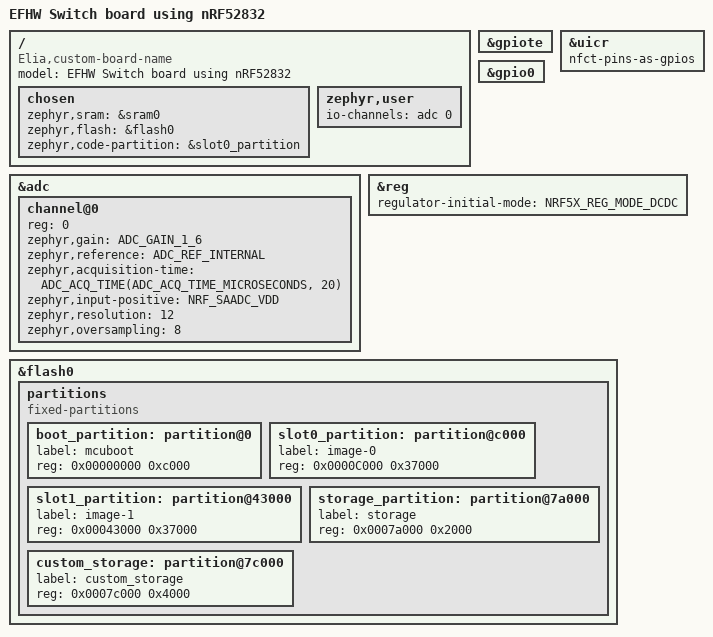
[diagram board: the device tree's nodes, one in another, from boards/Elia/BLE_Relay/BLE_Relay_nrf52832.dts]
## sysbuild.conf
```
SB_CONFIG_BOOTLOADER_MCUBOOT=y
SB_CONFIG_BOOT_SIGNATURE_KEY_FILE="${APP_DIR}/mykey.pem"
```

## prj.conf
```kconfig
#
# Copyright (c) 2020 Nordic Semiconductor
#
# SPDX-License-Identifier: LicenseRef-Nordic-5-Clause
#
CONFIG_NCS_SAMPLES_DEFAULTS=y
CONFIG_DK_LIBRARY=n
CONFIG_SYSTEM_WORKQUEUE_STACK_SIZE=2048
CONFIG_CLOCK_CONTROL_NRF_K32SRC_RC=y
CONFIG_SYSTEM_CLOCK_WAIT_FOR_STABILITY=y
CONFIG_CLOCK_CONTROL_NRF_K32SRC_500PPM=y  # Adjust as needed for power consumption vs. accuracy

CONFIG_BT_CTLR_TX_PWR_PLUS_4=y
CONFIG_FPU=y
CONFIG_CBPRINTF_FP_SUPPORT=y
CONFIG_CBPRINTF_FP_A_SUPPORT=y
CONFIG_BT_GAP_AUTO_UPDATE_CONN_PARAMS=y
CONFIG_BT_GAP_PERIPHERAL_PREF_PARAMS=y
CONFIG_ASSERT=n

CONFIG_BT_PERIPHERAL_PREF_MIN_INT=200
CONFIG_BT_PERIPHERAL_PREF_MAX_INT=200
CONFIG_BT_PERIPHERAL_PREF_LATENCY=0
CONFIG_BT_PERIPHERAL_PREF_TIMEOUT=200

CONFIG_ARM_MPU=y
CONFIG_HW_STACK_PROTECTION=y

CONFIG_CONSOLE=y
CONFIG_UART_CONSOLE=n
CONFIG_RTT_CONSOLE=y
CONFIG_LOG=y
CONFIG_USE_SEGGER_RTT=y
CONFIG_ADC=y
CONFIG_BT=y
CONFIG_BT_PERIPHERAL=y
CONFIG_BT_DEVICE_NAME="BR1"
CONFIG_BT_MAX_CONN=1
CONFIG_BT_SMP=y

# Enable the BMS service
CONFIG_BT_BMS=y

# Enable bonding
CONFIG_BT_SETTINGS=y
CONFIG_FLASH=y
CONFIG_FLASH_PAGE_LAYOUT=y
CONFIG_FLASH_MAP=y
CONFIG_NVS=y
CONFIG_SETTINGS_NVS=y
CONFIG_SETTINGS=y
CONFIG_BT_DEVICE_NAME_DYNAMIC=y

CONFIG_BT_SETTINGS_CCC_LAZY_LOADING=n

CONFIG_BOOTLOADER_MCUBOOT=y
#CONFIG_MCUMGR=y
#CONFIG_IMG_MANAGER=y
#CONFIG_STREAM_FLASH=y
#CONFIG_ZCBOR=y
#CONFIG_NET_BUF=y

CONFIG_NCS_SAMPLE_MCUMGR_BT_OTA_DFU=y
# CONFIG_MCUMGR=y
# CONFIG_NET_BUF=y
# CONFIG_ZCBOR=y
# CONFIG_CRC=y
# CONFIG_MCUMGR_TRANSPORT_BT=y
# CONFIG_MCUMGR_TRANSPORT_BT_CONN_PARAM_CONTROL=y
# CONFIG_IMG_MANAGER=y
# CONFIG_STREAM_FLASH=y
# CONFIG_MCUMGR_GRP_IMG=y
# CONFIG_MCUMGR_GRP_OS=y
# CONFIG_MCUMGR_GRP_OS_BOOTLOADER_INFO=y
# CONFIG_MCUMGR_TRANSPORT_BT_REASSEMBLY=y
# CONFIG_NCS_SAMPLE_MCUMGR_BT_OTA_DFU_SPEEDUP=y  

CONFIG_SIZE_OPTIMIZATIONS=y

CONFIG_TIMESLICING=n
#CONFIG_MINIMAL_LIBC_MALLOC=n

# Interrupts
CONFIG_DYNAMIC_INTERRUPTS=n
CONFIG_IRQ_OFFLOAD=n

# Boot
CONFIG_BOOT_BANNER=n
CONFIG_BOOT_DELAY=0

# Interrupts
CONFIG_DYNAMIC_INTERRUPTS=n
CONFIG_IRQ_OFFLOAD=n

# Drivers and peripherals
CONFIG_I2C=n
CONFIG_WATCHDOG=y
CONFIG_GPIO=y
CONFIG_SPI=n
CONFIG_SERIAL=y
```

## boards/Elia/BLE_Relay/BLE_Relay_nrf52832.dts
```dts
/dts-v1/;
#include <nordic/nrf52832_qfaa.dtsi>
#include "BLE_Relay-pinctrl.dtsi"

/ {
	model = "EFHW Switch board using nRF52832";
	compatible = "Elia,custom-board-name";

	chosen {
		zephyr,sram = &sram0;
		zephyr,flash = &flash0;
		zephyr,code-partition = &slot0_partition;
	};

	zephyr,user {
		io-channels = <&adc 0>;
	};
};

&adc {
	#address-cells = <1>;
	#size-cells = <0>;
	status = "okay";
	channel@0 {
		reg = <0>;
		zephyr,gain = "ADC_GAIN_1_6";
		zephyr,reference = "ADC_REF_INTERNAL";
		zephyr,acquisition-time = <ADC_ACQ_TIME(ADC_ACQ_TIME_MICROSECONDS, 20)>;
		zephyr,input-positive = <NRF_SAADC_VDD>;
		zephyr,resolution = <12>;
		zephyr,oversampling = <8>;
	};
};

/* &uicr {
	gpio-as-nreset;
}; */

&gpiote {
	status = "okay";
};

&uicr { nfct-pins-as-gpios; };
	
&gpio0 {
	status = "okay";
};

&reg {
	regulator-initial-mode = <NRF5X_REG_MODE_DCDC>;
};

&flash0 {
	partitions {
		compatible = "fixed-partitions";
		#address-cells = <1>;
		#size-cells = <1>;

		boot_partition: partition@0 {
			label = "mcuboot";
			reg = <0x00000000 0xc000>;
		};
		slot0_partition: partition@c000 {
			label = "image-0";
			reg = <0x0000C000 0x37000>;
		};
		slot1_partition: partition@43000 {
			label = "image-1";
			reg = <0x00043000 0x37000>;
		};
		storage_partition: partition@7a000 {
			label = "storage";
			reg = <0x0007a000 0x2000>;
		};
		custom_storage: partition@7c000 {
			label = "custom_storage";
			reg = <0x0007c000 0x4000>;
		};
	};
};
```

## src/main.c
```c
// SPDX-License-Identifier: GPL-3.0-or-later
// Copyright (c) 2024-2026 Elia Chiarucci

#include <zephyr/types.h>
#include <stddef.h>
#include <string.h>
#include <errno.h>
#include <zephyr/sys/printk.h>
#include <zephyr/sys/byteorder.h>
#include <zephyr/kernel.h>
#include <zephyr/logging/log.h>
#include <soc.h>
#include <zephyr/settings/settings.h>
#include <nrfx_gpiote.h>

LOG_MODULE_REGISTER(ble_relay, LOG_LEVEL_DBG);

#include "storage_manager.h"
#include "gpio_manager.h"
#include "status_led.h"
#include "adc.h"
#include "ble_manager.h"
#include "watchdog.h"

struct k_timer update_led_status_timer;

int main(void)
{
	watchdog_start();
	storage_manager_init();
	init_hw_revision();
	gpio_start();
	adc_start();
	status_led_init();
	ble_start();

	// Feed from the lowest-priority thread: if the kernel hangs or a higher-priority thread
	// never yields, feeding stops and the watchdog resets the switch
	k_thread_priority_set(k_current_get(), K_LOWEST_APPLICATION_THREAD_PRIO);
	for (;;)
	{
		watchdog_feed();
		k_sleep(K_MSEC(WATCHDOG_FEED_INTERVAL_MS));
	}
}
```

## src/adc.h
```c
// SPDX-License-Identifier: GPL-3.0-or-later
// Copyright (c) 2024-2026 Elia Chiarucci

#pragma once

#include <zephyr/drivers/adc.h>
#include <zephyr/logging/log.h>

static const struct adc_dt_spec adc_channel = ADC_DT_SPEC_GET_BY_IDX(DT_PATH(zephyr_user), 0);

int16_t buf; // Buffer for ADC result
struct adc_sequence sequence = {
	.buffer = &buf,
	.buffer_size = sizeof(buf),
};

float get_battery_voltage()
{
	adc_read_dt(&adc_channel, &sequence);
	float voltage_value = (buf * 3.6) / 4096 + 0.05;
	return voltage_value;
}

int adc_start()
{
	int err;
	if (!adc_is_ready_dt(&adc_channel))
	{
		LOG_ERR("ADC controller devivce %s not ready", adc_channel.dev->name);
		return 0;
	}

	err = adc_channel_setup_dt(&adc_channel);
	if (err < 0)
	{
		LOG_ERR("Could not setup channel #%d (%d)", 2, err);
		return 0;
	}
	else
	{
		LOG_INF("Correctly set up ADC!");
	}

	err = adc_sequence_init_dt(&adc_channel, &sequence);
	if (err < 0)
	{
		LOG_ERR("Could not initalize sequnce");
		return 0;
	}
}

// Read handler for the battery level characteristic
static ssize_t read_battery_level(struct bt_conn *conn, const struct bt_gatt_attr *attr, void *buf,
								  uint16_t len, uint16_t offset)
{
	int16_t battery_voltage = get_battery_voltage() * 100;
	// Simply return the battery level (percent)
	return bt_gatt_attr_read(conn, attr, buf, len, offset, &battery_voltage,
							 sizeof(battery_voltage));
}
```

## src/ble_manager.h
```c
// SPDX-License-Identifier: GPL-3.0-or-later
// Copyright (c) 2024-2026 Elia Chiarucci

#pragma once

#include <bluetooth/services/bms.h>
#include <zephyr/bluetooth/bluetooth.h>
#include <zephyr/bluetooth/conn.h>
#include <zephyr/bluetooth/gatt.h>
#include <zephyr/bluetooth/hci.h>
#include <zephyr/bluetooth/uuid.h>
#include <zephyr/toolchain.h>

#define DEVICE_NAME CONFIG_BT_DEVICE_NAME
#define DEVICE_NAME_LEN (sizeof(DEVICE_NAME) - 1)

/* Authorization code for Bond Management Service
 * In hex: {0x41, 0x42, 0x43, 0x44}
 */
static const uint8_t bms_auth_code[] = {'A', 'B', 'C', 'D'};

#define CUSTOM_SERVICE_UUID                                                    \
  BT_UUID_128_ENCODE(0x67d03ad6, 0x34ba, 0x450a, 0xa39c, 0x00805f9b34fb)

#define BT_UUID_AUTOMATION_IO BT_UUID_DECLARE_16(0x1815)
#define BT_UUID_DIGITAL BT_UUID_DECLARE_16(0x2A56)

#define BT_UUID_BATTERY BT_UUID_DECLARE_16(0x180F)
#define BT_UUID_BATTERY_LEVEL BT_UUID_DECLARE_16(0x2A19)
#define BT_UUID_PRESENTATION_FORMAT BT_UUID_DECLARE_16(0x2904)

#define BT_UUID_CUSTOM_DEVICE_NAME_VAL                                         \
  BT_UUID_128_ENCODE(0x397bfacd, 0xf6c0, 0x470e, 0x8c72, 0x5b17d34e1259)
#define BT_UUID_CUSTOM_DEVICE_NAME                                             \
  BT_UUID_DECLARE_128(BT_UUID_CUSTOM_DEVICE_NAME_VAL)

#define BT_UUID_DEVICE_INFO                                                    \
  BT_UUID_DECLARE_16(0x180A) // Device Information Service
#define BT_UUID_FIRMWARE_REVISION                                              \
  BT_UUID_DECLARE_16(0x2A26) // Firmware Revision String
#define BT_UUID_HARDWARE_REVISION                                              \
  BT_UUID_DECLARE_16(0x2A27) // Hardware Revision String
#define BT_UUID_MODEL_NUMBER                                                   \
  BT_UUID_DECLARE_16(0x2A24) // Model Number String0x2A24

static const struct bt_le_conn_param *conn_params = BT_LE_CONN_PARAM(
    CONFIG_BT_PERIPHERAL_PREF_MIN_INT, CONFIG_BT_PERIPHERAL_PREF_MAX_INT,
    CONFIG_BT_PERIPHERAL_PREF_LATENCY, CONFIG_BT_PERIPHERAL_PREF_TIMEOUT);

// Presentation Format Descriptor for Voltage Level (scaled by 100, unit: volts)
static const uint8_t voltage_level_cpf[7] = {
    0x10, // Format: unsigned 16-bit integer
    0x00, // Exponent: no scaling (1.0)
    0x00, // Unit: Volts (0x2703)
    0x03, // Unit: Volts (0x2703)
    0x00, // Additional flags (reserved)
    0x00, // Reserved
    0x00  // Reserved
};

static const struct bt_data ad[] = {
    BT_DATA_BYTES(BT_DATA_FLAGS, (BT_LE_AD_GENERAL | BT_LE_AD_NO_BREDR)),
    BT_DATA(BT_DATA_NAME_COMPLETE, DEVICE_NAME, DEVICE_NAME_LEN),
};

static const struct bt_data sd[] = {
    BT_DATA_BYTES(BT_DATA_UUID128_ALL, CUSTOM_SERVICE_UUID),
};

static ssize_t read_firmware_revision(struct bt_conn *conn,
                                      const struct bt_gatt_attr *attr,
                                      void *buf, uint16_t len,
                                      uint16_t offset) {
  uint8_t firmware_revision[] = {0, 1, 9};
  return bt_gatt_attr_read(conn, attr, buf, len, offset, &firmware_revision,
                           sizeof(firmware_revision));
}

static ssize_t read_hardware_revision(struct bt_conn *conn,
                                      const struct bt_gatt_attr *attr,
                                      void *buf, uint16_t len,
                                      uint16_t offset) {
  uint32_t hw_rev;
  int rc;

  // Read the hardware revision integer from NVS
  rc = read_hw_revision(&hw_rev);
  if (rc < 0) {
    LOG_ERR("Failed to read hardware revision (err %d)", rc);
    hw_rev = 0; // Default value if read fails
  }

  // Return the raw byte representation
  return bt_gatt_attr_read(conn, attr, buf, len, offset, &hw_rev,
                           sizeof(hw_rev));
}

static ssize_t read_model(struct bt_conn *conn, const struct bt_gatt_attr *attr,
                          void *buf, uint16_t len, uint16_t offset) {
  char model[] = "BR1";
  return bt_gatt_attr_read(conn, attr, buf, len, offset, model, strlen(model));
}

void update_advertising_data(char adv_name) {
  write_adv_name(adv_name, true);
  sys_reboot(1);
  return;
}

static ssize_t update_ble_name(struct bt_conn *conn,
                               const struct bt_gatt_attr *attr, void *buf,
                               uint16_t len, uint16_t offset) {
  // Check if there's an offset (shouldn't happen for this attribute)
  if (offset > 0) {
    return BT_GATT_ERR(BT_ATT_ERR_INVALID_OFFSET);
  }

  // Check if length exceeds expected bounds
  if (len > 31) {
    LOG_ERR("Buffer length exceeds maximum allowed size.");
    return BT_GATT_ERR(BT_ATT_ERR_INVALID_ATTRIBUTE_LEN);
  }

  // Allocate a local buffer and copy data
  char local_buf[32]; // Size to hold 31 chars plus null terminator
  memcpy(local_buf, buf, len);

  // Ensure null termination
  local_buf[len] = '\0';

  // Log the received string
  LOG_INF("Received string (len=%u): %s", len, local_buf);

  // Process the data
  write_adv_name(local_buf, true);

  // Return the number of bytes read
  return len;
}

BT_GATT_SERVICE_DEFINE(
    gpio_svc, BT_GATT_PRIMARY_SERVICE(BT_UUID_AUTOMATION_IO),
    BT_GATT_CHARACTERISTIC(BT_UUID_DIGITAL,
                           BT_GATT_CHRC_READ | BT_GATT_CHRC_WRITE,
                           BT_GATT_PERM_READ | BT_GATT_PERM_WRITE, read_relay,
                           set_relay, NULL),
    BT_GATT_PRIMARY_SERVICE(BT_UUID_BATTERY),
    BT_GATT_CHARACTERISTIC(BT_UUID_BATTERY_LEVEL, BT_GATT_CHRC_READ,
                           BT_GATT_PERM_READ, read_battery_level, NULL, NULL),
    BT_GATT_PRIMARY_SERVICE(BT_UUID_CUSTOM_DEVICE_NAME),
    BT_GATT_CHARACTERISTIC(BT_UUID_CUSTOM_DEVICE_NAME, BT_GATT_CHRC_WRITE,
                           BT_GATT_PERM_WRITE, NULL, update_ble_name, NULL),
    BT_GATT_PRIMARY_SERVICE(BT_UUID_DEVICE_INFO),
    BT_GATT_CHARACTERISTIC(BT_UUID_FIRMWARE_REVISION, BT_GATT_CHRC_READ,
                           BT_GATT_PERM_READ, read_firmware_revision, NULL,
                           NULL),
    BT_GATT_CHARACTERISTIC(BT_UUID_HARDWARE_REVISION, BT_GATT_CHRC_READ,
                           BT_GATT_PERM_READ, read_hardware_revision, NULL,
                           NULL),
    BT_GATT_CHARACTERISTIC(BT_UUID_MODEL_NUMBER, BT_GATT_CHRC_READ,
                           BT_GATT_PERM_READ, read_model, NULL, NULL),
    BT_GATT_DESCRIPTOR(BT_UUID_PRESENTATION_FORMAT, BT_GATT_PERM_READ, NULL,
                       NULL, voltage_level_cpf));

static void connected(struct bt_conn *conn, uint8_t err) {
  if (err) {
    LOG_INF("Connection failed (err %u)\n", err);
    return;
  }
  // Suggest a connection parameter update // not needed if
  // CONFIG_BT_GAP_AUTO_UPDATE_CONN_PARAMS is set in config
  /* 	int update_err = bt_conn_le_param_update(conn, conn_params);
          if (update_err)
          {
                  printk("Connection parameter update failed (err %d)\n",
     update_err);
          } */
  status_led_update(CONNECTED);
  LOG_INF("Connected\n");
}

static void disconnected(struct bt_conn *conn, uint8_t reason) {
  status_led_update(ADVERTISING);
  LOG_INF("Disconnected (reason %u)\n", reason);
}

static void security_changed(struct bt_conn *conn, bt_security_t level,
                             enum bt_security_err err) {
  char addr[BT_ADDR_LE_STR_LEN];

  bt_addr_le_to_str(bt_conn_get_dst(conn), addr, sizeof(addr));

  if (!err) {
    LOG_INF("Security changed: %s level %u\n", addr, level);
  } else {
    LOG_INF("Security failed: %s level %u err %d\n", addr, level, err);
  }
}

BT_CONN_CB_DEFINE(conn_callbacks) = {
    .connected = connected,
    .disconnected = disconnected,
    .security_changed = security_changed,
};

static void auth_passkey_display(struct bt_conn *conn, unsigned int passkey) {
  char addr[BT_ADDR_LE_STR_LEN];

  bt_addr_le_to_str(bt_conn_get_dst(conn), addr, sizeof(addr));

  LOG_INF("Passkey for %s: %06u\n", addr, passkey);
}

static void auth_cancel(struct bt_conn *conn) {
  char addr[BT_ADDR_LE_STR_LEN];

  bt_addr_le_to_str(bt_conn_get_dst(conn), addr, sizeof(addr));

  LOG_INF("Pairing cancelled: %s\n", addr);
}

static void pairing_complete(struct bt_conn *conn, bool bonded) {
  char addr[BT_ADDR_LE_STR_LEN];

  bt_addr_le_to_str(bt_conn_get_dst(conn), addr, sizeof(addr));

  LOG_INF("Pairing completed: %s, bonded: %d\n", addr, bonded);
}

static void pairing_failed(struct bt_conn *conn, enum bt_security_err reason) {
  char addr[BT_ADDR_LE_STR_LEN];

  bt_addr_le_to_str(bt_conn_get_dst(conn), addr, sizeof(addr));

  LOG_INF("Pairing failed conn: %s, reason %d\n", addr, reason);
}

static void pairing_confirm(struct bt_conn *conn) {
  LOG_INF("Accepting pairing request");
  bt_conn_auth_pairing_confirm(conn);
}

static struct bt_conn_auth_cb conn_auth_callbacks = {
    .passkey_display = NULL, // auth_passkey_display,
    .pairing_confirm = pairing_confirm,
    .cancel = auth_cancel,
};

static struct bt_conn_auth_info_cb conn_auth_info_callbacks = {
    .pairing_complete = pairing_complete, .pairing_failed = pairing_failed};

static bool bms_authorize(struct bt_conn *conn,
                          struct bt_bms_authorize_params *params) {
  if ((params->code_len == sizeof(bms_auth_code)) &&
      (memcmp(bms_auth_code, params->code, sizeof(bms_auth_code)) == 0)) {
    LOG_INF("Authorization of BMS operation is successful\n");
    return true;
  }

  LOG_INF("Authorization of BMS operation has failed\n");
  return false;
}

static struct bt_bms_cb bms_callbacks = {
    .authorize = bms_authorize,
};

static int bms_init(void) {
  struct bt_bms_init_params init_params = {0};

  /* Enable all possible operation codes */
  init_params.features.delete_requesting.supported = true;
  init_params.features.delete_rest.supported = true;
  init_params.features.delete_all.supported = true;

  /* Require authorization code for operations that
   * also delete bonding information for other devices
   * than the requesting client.
   */
  init_params.features.delete_rest.authorize = true;
  init_params.features.delete_all.authorize = true;

  init_params.cbs = &bms_callbacks;

  return bt_bms_init(&init_params);
}

static char bt_name[32];

static int get_saved_bt_name(const char *name, size_t len,
                             settings_read_cb read_cb, void *cb_arg) {
  if (strcmp(name, "bt_name") == 0) {
    if (len > sizeof(bt_name) - 1) {
      return -ENOMEM; // Error: buffer too small
    }
    ssize_t ret = read_cb(cb_arg, bt_name, len);
    if (ret > 0) {
      bt_name[ret] = '\0'; // Null-terminate the string
    }
    return 0;
  }
  return -ENOENT; // Key not found
}

struct settings_handler settings_conf = {.name = "bt_name",
                                         .h_set = get_saved_bt_name};

void ble_start() {
  LOG_INF("Starting Bluetooth Peripheral BMS example\n");
  int err;

  err = bt_conn_auth_cb_register(&conn_auth_callbacks);
  if (err) {
    LOG_INF("Failed to register authorization callbacks.\n");
    return;
  }

  err = bt_conn_auth_info_cb_register(&conn_auth_info_callbacks);
  if (err) {
    LOG_INF("Failed to register authorization info callbacks.\n");
    return;
  }

  err = bt_enable(NULL);
  if (err) {
    LOG_INF("Bluetooth init failed (err %d)\n", err);
    return;
  }

  LOG_INF("Bluetooth initialized\n");

  if (IS_ENABLED(CONFIG_SETTINGS)) {
    settings_load();
  }

  struct bt_le_adv_param adv_params = *(BT_LE_ADV_CONN);
  adv_params.interval_max = 2400;
  adv_params.interval_min = 2400;

  struct bt_data ad[2] = {
      BT_DATA_BYTES(BT_DATA_FLAGS, (BT_LE_AD_GENERAL | BT_LE_AD_NO_BREDR))};

  char *name = read_adv_name();
  if (!name) {
    name = DEVICE_NAME;
  }
  LOG_INF("Name: %s\n", name);
  struct bt_data data = BT_DATA(BT_DATA_NAME_COMPLETE, name, strlen(name));
  ad[1] = data;

  err = bt_le_adv_start(&adv_params, ad, ARRAY_SIZE(ad), sd, ARRAY_SIZE(sd));
  if (err) {
    LOG_ERR("Advertising failed to start (err %d)\n", err);
    return;
  };
  status_led_start(ADVERTISING);
  LOG_INF("Advertising successfully started\n");
}
```

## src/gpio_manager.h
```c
// SPDX-License-Identifier: GPL-3.0-or-later
// Copyright (c) 2024-2026 Elia Chiarucci

#pragma once

#include <zephyr/device.h>
#include <zephyr/devicetree.h>
#include <zephyr/drivers/gpio.h>
#include <zephyr/bluetooth/gatt.h>

#define GPIO_NODE DT_NODELABEL(gpio0) // Assuming GPIO port 0
#define GPIO_STATUS_LED 7			  // Pin 7
#define GPIO_RELAY_STATUS 10		  // Pin 10
#define GPIO_RELAY_SET 8			  // Pin 8
#define GPIO_RELAY_RESET 9			  // Pin 9

static struct device *gpio_dev;
static struct k_timer relay_timer;

int get_relay_status()
{
	int err;
	err = gpio_pin_configure(gpio_dev, GPIO_RELAY_STATUS, GPIO_INPUT | GPIO_PULL_UP);
	if (err < 0)
	{
		LOG_INF("Failed to configure GPIO pin %d\n", GPIO_RELAY_STATUS);
		return err;
	}
	int relay_status = gpio_pin_get(gpio_dev, GPIO_RELAY_STATUS);
	err = gpio_pin_configure(gpio_dev, GPIO_RELAY_STATUS, GPIO_INPUT | GPIO_DISCONNECTED);
	if (err < 0)
	{
		LOG_INF("Failed to configure GPIO pin %d\n", GPIO_RELAY_STATUS);
		return err;
	}
	return relay_status;
}

void relay_timer_handler(struct k_timer *timer_id)
{
	gpio_pin_set(gpio_dev, GPIO_RELAY_SET, 0);
	gpio_pin_set(gpio_dev, GPIO_RELAY_RESET, 0);
	LOG_INF("DONE");
}

void relay_on()
{
	LOG_INF("TURNING ON");
	gpio_pin_set(gpio_dev, GPIO_RELAY_RESET, 0); // never drive both coils at once
	gpio_pin_set(gpio_dev, GPIO_RELAY_SET, 1);
	k_timer_start(&relay_timer, K_MSEC(10), K_NO_WAIT); // Schedule to turn off in 10ms
}

void relay_off()
{
	LOG_INF("TURNING OFF");
	gpio_pin_set(gpio_dev, GPIO_RELAY_SET, 0); // never drive both coils at once
	gpio_pin_set(gpio_dev, GPIO_RELAY_RESET, 1);
	k_timer_start(&relay_timer, K_MSEC(10), K_NO_WAIT); // Schedule to turn off in 10ms
}

static ssize_t read_relay(struct bt_conn *conn, const struct bt_gatt_attr *attr, const void *buf,
						  uint16_t len, uint16_t offset, uint8_t flags)
{
	int relay_status = get_relay_status();
	return bt_gatt_attr_read(conn, attr, buf, len, offset, &relay_status, sizeof(relay_status));
}

static ssize_t set_relay(struct bt_conn *conn, const struct bt_gatt_attr *attr, const void *buf,
						 uint16_t len, uint16_t offset, uint8_t flags)
{
	uint8_t value = *((uint8_t *)buf);
	LOG_INF("Integer: %d.", value);
	if (value == 1)
	{
		relay_on();
	}
	else
	{
		relay_off();
	}

	return len;
}

int gpio_start()
{
	int err;
	k_timer_init(&relay_timer, relay_timer_handler, NULL);
	
	/* Get device binding from the DeviceTree */
	gpio_dev = DEVICE_DT_GET(GPIO_NODE);
	if (!device_is_ready(gpio_dev))
	{
		LOG_INF("GPIO device is not ready\n");
		return -1;
	}

	/* Configure the pin as an output */
	err = gpio_pin_configure(gpio_dev, GPIO_STATUS_LED, GPIO_OUTPUT_INACTIVE);
	if (err < 0)
	{
		LOG_INF("Failed to configure GPIO pin %d\n", GPIO_STATUS_LED);
		return err;
	}

	err = gpio_pin_configure(gpio_dev, GPIO_RELAY_SET, GPIO_OUTPUT_INACTIVE);
	if (err < 0)
	{
		LOG_INF("Failed to configure GPIO pin %d\n", GPIO_RELAY_SET);
		return err;
	}

	err = gpio_pin_configure(gpio_dev, GPIO_RELAY_RESET, GPIO_OUTPUT_INACTIVE);
	if (err < 0)
	{
		LOG_INF("Failed to configure GPIO pin %d\n", GPIO_RELAY_RESET);
		return err;
	}
	err = gpio_pin_configure(gpio_dev, GPIO_RELAY_STATUS, GPIO_INPUT | GPIO_DISCONNECTED);
	if (err < 0)
	{
		LOG_INF("Failed to configure GPIO pin %d\n", GPIO_RELAY_STATUS);
		return err;
	}

	LOG_INF("GPIO started successfully!");
	return 0;
}
```

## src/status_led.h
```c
// SPDX-License-Identifier: GPL-3.0-or-later
// Copyright (c) 2024-2026 Elia Chiarucci

#pragma once

#include <zephyr/kernel.h>
#include <zephyr/logging/log.h>
#include "gpio_manager.h"

static struct k_timer led_timer;

typedef struct
{
    int duration;
    bool state;
} led_blink_step_t;

#define low_battery_led_steps_size 2
const led_blink_step_t low_battery_led_steps[low_battery_led_steps_size] = {
    {.duration = 75, .state = true},
    {.duration = 5000, .state = false},
};

#define advertising_led_steps_size 6
const led_blink_step_t advertising_led_steps[advertising_led_steps_size] = {
    {.duration = 300, .state = true},
    {.duration = 150, .state = false},
    {.duration = 300, .state = true},
    {.duration = 150, .state = false},
    {.duration = 300, .state = true},
    {.duration = 5000, .state = false},
};

#define connected_led_steps_size 2
const led_blink_step_t connected_led_steps[connected_led_steps_size] = {
    {.duration = 750, .state = true},
    {.duration = 5000, .state = false},
};

enum led_blink_status
{
    BATTERY_LOW,
    ADVERTISING,
    CONNECTED
};

enum led_blink_status current_led_blink_status = ADVERTISING;

int led_timing_step = 0;

int get_timing(led_blink_step_t *timing)
{
    led_blink_step_t *led_steps;
    int led_steps_size;
    switch (current_led_blink_status)
    {
    case BATTERY_LOW:
        led_steps = low_battery_led_steps;
        led_steps_size = low_battery_led_steps_size;
        break;
    case ADVERTISING:
        led_steps = advertising_led_steps;
        led_steps_size = advertising_led_steps_size;
        break;
    case CONNECTED:
        led_steps = connected_led_steps;
        led_steps_size = connected_led_steps_size;
        break;
    default:
        return -1;
        break;
    }
    if (led_timing_step >= led_steps_size)
    {
        led_timing_step = 0;
    };
    *timing = led_steps[led_timing_step];
    led_timing_step++;
    return 0;
}

void timer_handler()
{
    // uint32_t pin_state = nrf_gpio_pin_out_read(GPIO_STATUS_LED);
    led_blink_step_t timing;
    int err = get_timing(&timing);
    if (err < 0)
    {
        LOG_ERR("Error getting timing");
        led_timing_step = 0;
        k_timer_start(&led_timer, K_MSEC(100), K_NO_WAIT);
        return;
    }
    int ms = timing.duration;
    gpio_pin_set(gpio_dev, GPIO_STATUS_LED, timing.state ? 1 : 0);
    k_timer_start(&led_timer, K_MSEC(ms), K_NO_WAIT);
}

void status_led_init()
{
    k_timer_init(&led_timer, timer_handler, NULL);
}

void status_led_update(enum led_blink_status status)
{
    led_timing_step = 0;
    current_led_blink_status = status;
}

void status_led_start(enum led_blink_status status)
{
    current_led_blink_status = status;
    timer_handler();
}
```

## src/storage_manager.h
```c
// SPDX-License-Identifier: GPL-3.0-or-later
// Copyright (c) 2024-2026 Elia Chiarucci

#pragma once

#include <zephyr/kernel.h>
#include <zephyr/device.h>
#include <string.h>
#include <zephyr/drivers/flash.h>
#include <zephyr/random/rand32.h>
#include <zephyr/storage/flash_map.h>
#include <zephyr/fs/nvs.h>

#define STORAGE_THREAD_STACK_SIZE 1024
#define STORAGE_THREAD_PRIORITY 7
#define NVS_PARTITION_DEVICE FIXED_PARTITION_DEVICE(custom_storage)
#define NVS_PARTITION_OFFSET FIXED_PARTITION_OFFSET(custom_storage)

#define DEVICE_HW_REVISION 1

#define HW_REV_KEY 1
#define ADV_NAME_KEY 0

static struct nvs_fs fs;

int storage_manager_init()
{
    int rc = 0;
    struct flash_pages_info info;
    /* define the nvs file system by settings with:
     *	sector_size equal to the pagesize,
     *	3 sectors
     *	starting at NVS_PARTITION_OFFSET
     */
    fs.flash_device = NVS_PARTITION_DEVICE;
    if (!device_is_ready(fs.flash_device))
    {
        LOG_ERR("Flash device %s is not ready\n", fs.flash_device->name);
        return -1;
    }
    fs.offset = NVS_PARTITION_OFFSET;
    rc = flash_get_page_info_by_offs(fs.flash_device, fs.offset, &info);
    if (rc)
    {
        LOG_ERR("Unable to get page info, rc=%d\n", rc);
        return -1;
    }
    fs.sector_size = info.size;
    fs.sector_count = 4U;

    rc = nvs_mount(&fs);
    if (rc)
    {
        LOG_ERR("Flash Init failed, rc=%d\n", rc);
        return -1;
    }

    return 0;
}

void write_adv_name(char *name, bool reboot)
{
    char buf[32];
    size_t name_len = strlen(name);

    if (name_len >= sizeof(buf))
    {
        LOG_ERR("Name too long (%u bytes), max allowed is %u",
                name_len, sizeof(buf) - 1);
        return;
    }

    strcpy(buf, name);
    LOG_INF("Writing %s to flash\n", buf);
    nvs_write(&fs, ADV_NAME_KEY, buf, name_len + 1);
    if (reboot)
    {
        sys_reboot(1);
    }
}

char *read_adv_name()
{
    static char buf[32];
    ssize_t err = nvs_read(&fs, ADV_NAME_KEY, buf, sizeof(buf));

    if (err < 0)
    {
        printk("Flash read failed, err=%zd\n", err);
        // Ensure the random number is within the 8-digit range
        uint32_t random_id = 10000000 + (sys_rand32_get() % 90000000);
        snprintf(buf, sizeof(buf), "BR1_%d", random_id);
        LOG_INF("New adv name created: %s\n", buf);
        write_adv_name(buf, false);
        return buf;
    }

    LOG_INF("Read back: %s\n", buf);
    return buf;
};

// Function to write hardware revision to NVS
int write_hw_revision(uint32_t revision)
{
    int rc = nvs_write(&fs, HW_REV_KEY, &revision, sizeof(revision));
    if (rc < 0)
    {
        LOG_ERR("Failed to write hardware revision to NVS (err %d)", rc);
        return rc;
    }

    LOG_INF("Hardware revision '%u' written to flash", revision);
    return 0;
}

// Function to read hardware revision from NVS
int read_hw_revision(uint32_t *revision)
{
    if (!revision)
    {
        return -EINVAL;
    }

    int rc = nvs_read(&fs, HW_REV_KEY, revision, sizeof(*revision));
    if (rc < 0 && rc != -ENOENT)
    {
        LOG_ERR("Failed to read hardware revision from NVS (err %d)", rc);
        return rc;
    }

    if (rc == -ENOENT)
    {
        LOG_WRN("No hardware revision found in NVS");
        *revision = 0; // Default to 0 if not found
        return rc;
    }

    LOG_INF("Read hardware revision: '%u'", *revision);
    return 0;
}

// This function should be called during device initialization
int init_hw_revision(void)
{
    uint32_t current_rev;
    int rc = read_hw_revision(&current_rev);

    // -ENOENT (never written, current_rev = 0) is the case that must go on and write it
    if (rc < 0 && rc != -ENOENT)
    {
        return rc;
    }

    // If hardware revision is not set (0), set it
    if (current_rev == 0)
    {
        // Define your hardware revision integer here or pass it as a build variable
        uint32_t hw_rev = DEVICE_HW_REVISION;
        if (hw_rev == 0)
        {
            hw_rev = 1; // Default value if not defined
        }

        rc = write_hw_revision(hw_rev);
        if (rc < 0)
        {
            LOG_ERR("Failed to initialize hardware revision");
            return rc;
        }

        LOG_INF("Hardware revision initialized to '%u'", hw_rev);
    }
    else
    {
        LOG_INF("Using existing hardware revision: '%u'", current_rev);
    }

    return 0;
}
```

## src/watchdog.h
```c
// SPDX-License-Identifier: GPL-3.0-or-later
// Copyright (c) 2024-2026 Elia Chiarucci

#pragma once

#include <zephyr/device.h>
#include <zephyr/drivers/watchdog.h>
#include <zephyr/logging/log.h>

#define WATCHDOG_TIMEOUT_MS 30000
#define WATCHDOG_FEED_INTERVAL_MS 5000

static const struct device *const wdt_dev = DEVICE_DT_GET(DT_NODELABEL(wdt0));
static int wdt_channel = -1;

// Starts the hardware watchdog: the SoC resets if it isn't fed for WATCHDOG_TIMEOUT_MS.
// Once started it can't be stopped and keeps running across soft reboots (MCUboot feeds it).
int watchdog_start()
{
	if (!device_is_ready(wdt_dev))
	{
		LOG_ERR("Watchdog device not ready");
		return -1;
	}

	struct wdt_timeout_cfg cfg = {
		.window.min = 0,
		.window.max = WATCHDOG_TIMEOUT_MS,
		.callback = NULL,
		.flags = WDT_FLAG_RESET_SOC,
	};
	wdt_channel = wdt_install_timeout(wdt_dev, &cfg);
	if (wdt_channel < 0)
	{
		LOG_ERR("Watchdog install failed (err %d)", wdt_channel);
		return wdt_channel;
	}

	// Keeps counting while the CPU sleeps; pauses only while a debugger halts it
	int err = wdt_setup(wdt_dev, WDT_OPT_PAUSE_HALTED_BY_DBG);
	if (err < 0)
	{
		LOG_ERR("Watchdog setup failed (err %d)", err);
		wdt_channel = -1;
		return err;
	}

	LOG_INF("Watchdog started (%d ms)", WATCHDOG_TIMEOUT_MS);
	return 0;
}

void watchdog_feed()
{
	if (wdt_channel >= 0)
	{
		wdt_feed(wdt_dev, wdt_channel);
	}
}
```
